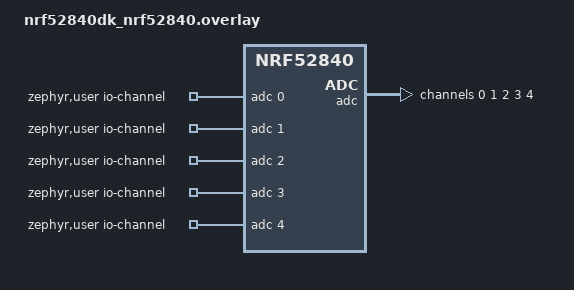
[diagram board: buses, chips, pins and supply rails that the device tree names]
/* boards/nrf52840dk_nrf52840.overlay */

/ {
	zephyr,user {
		/* Five channels: &adc + channel index */
		io-channels = <&adc 0>, <&adc 1>, <&adc 2>, <&adc 3>, <&adc 4>;
	};
};

&adc {
	status = "okay";
	#address-cells = <1>;
	#size-cells = <0>;

	/* Channel 0 -> AIN0 */
	channel@0 {
		reg = <0>;
		zephyr,gain = "ADC_GAIN_1_6";
		zephyr,reference = "ADC_REF_INTERNAL";
		zephyr,acquisition-time = <ADC_ACQ_TIME(ADC_ACQ_TIME_MICROSECONDS, 40)>;
		zephyr,input-positive = <NRF_SAADC_AIN0>;
		zephyr,resolution = <12>;
	};

	channel@1 {
		reg = <1>;
		zephyr,gain = "ADC_GAIN_1_6";
		zephyr,reference = "ADC_REF_INTERNAL";
		zephyr,acquisition-time = <ADC_ACQ_TIME(ADC_ACQ_TIME_MICROSECONDS, 40)>;
		zephyr,input-positive = <NRF_SAADC_AIN1>;
		zephyr,resolution = <12>;
	};

	channel@2 {
		reg = <2>;
		zephyr,gain = "ADC_GAIN_1_6";
		zephyr,reference = "ADC_REF_INTERNAL";
		zephyr,acquisition-time = <ADC_ACQ_TIME(ADC_ACQ_TIME_MICROSECONDS, 40)>;
		zephyr,input-positive = <NRF_SAADC_AIN2>;
		zephyr,resolution = <12>;
	};

	channel@3 {
		reg = <3>;
		zephyr,gain = "ADC_GAIN_1_6";
		zephyr,reference = "ADC_REF_INTERNAL";
		zephyr,acquisition-time = <ADC_ACQ_TIME(ADC_ACQ_TIME_MICROSECONDS, 40)>;
		zephyr,input-positive = <NRF_SAADC_AIN3>;
		zephyr,resolution = <12>;
	};

	channel@4 {
		reg = <4>;
		zephyr,gain = "ADC_GAIN_1_6";
		zephyr,reference = "ADC_REF_INTERNAL";
		zephyr,acquisition-time = <ADC_ACQ_TIME(ADC_ACQ_TIME_MICROSECONDS, 40)>;
		zephyr,input-positive = <NRF_SAADC_AIN4>;
		zephyr,resolution = <12>;
	};
};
